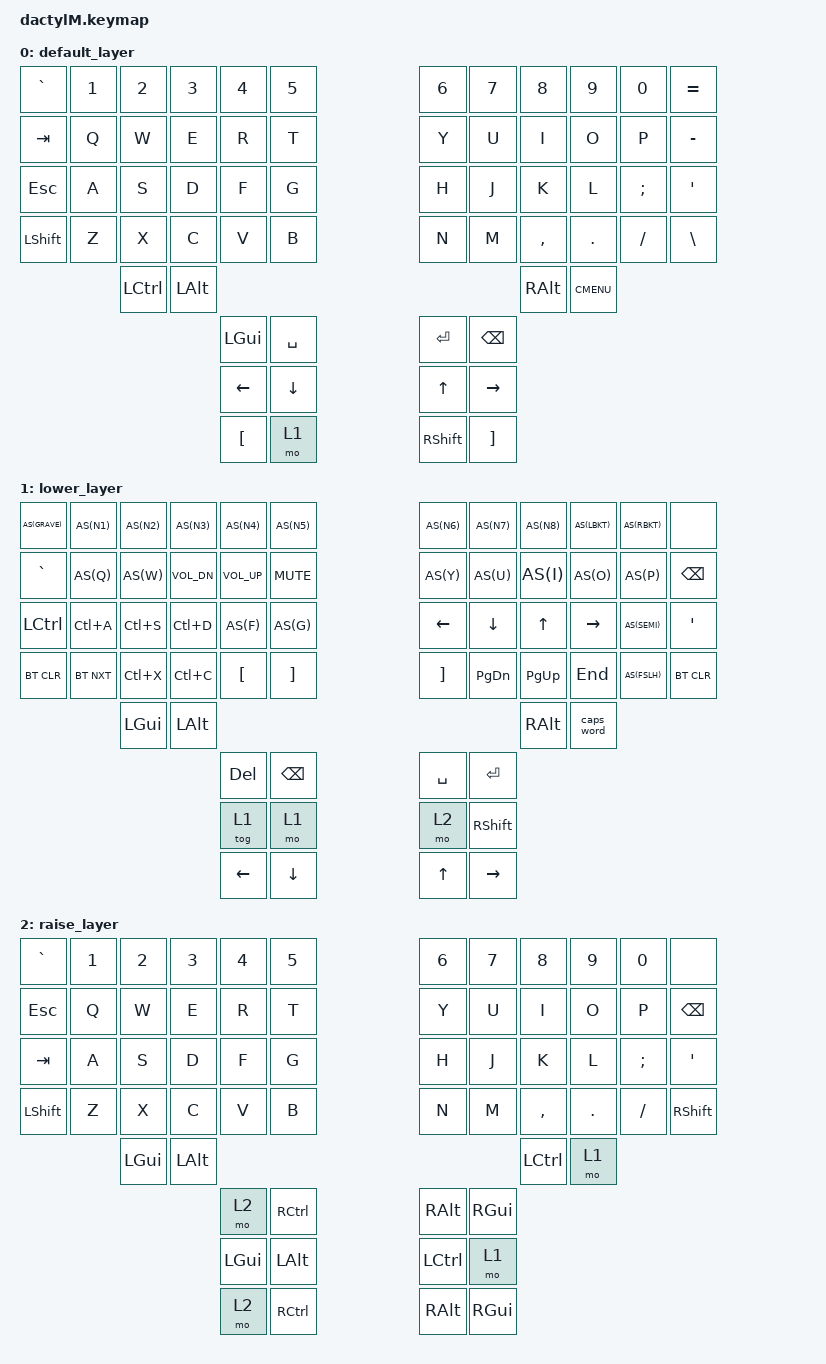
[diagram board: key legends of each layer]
/*
 * Copyright (c) 2020 The ZMK Contributors
 *
 * SPDX-License-Identifier: MIT
 */
/**/

#include <behaviors.dtsi>
#include <dt-bindings/zmk/keys.h>
#include <dt-bindings/zmk/bt.h>



#define DEFAULT 0
#define Movement 1
#define NumPad 2
#define Macro 3
#define Mouse 4

#define AS(keycode) &as LS(keycode) keycode

/ {
        behaviors {
            as: auto_shift {
                compatible = "zmk,behavior-hold-tap";
                label = "AUTO_SHIFT";
                #binding-cells = <2>;
                tapping_term_ms = <200>;
                quick_tap_ms = <10>;
                flavor = "tap-preferred";
                bindings = <&kp>, <&kp>;
            };
        };


    keymap {
        compatible = "zmk,keymap";

        default_layer {
// ------------------------------------------------------------------------------------------------------------
// |  ESC  |  1  |  2  |  3   |  4   |  5    |                   |  6   |  7     |  8    |  9   |   0   | CLR_BT |
// |  TAB  |  Q  |  W  |  E   |  R   |  T    |                   |  Y   |  U     |  I    |  O   |   P   | BKSPC  |
// |  CTRL |  A  |  S  |  D   |  F   |  G    |                   |  H   |  J     |  K    |  L   |   ;   |   '    |
// | SHIFT |  Z  |  X  |  C   |  V   |  B    |                   |  N   |  M     |  ,    |  .   |   /   | SHIFT  |
//               | GUI | ALT  |                                                  | ALT   | GUI  |
//                            | DEL  | BKSPC |                   | SPACE | ENTR  |
//                            | Lyr4 | Lyr1  |                   | Lyr2  | Lyr3  |
//                            | LEFT | DOWN  |                   | UP    | RIGHT |
            bindings = <
&kp GRAVE  &kp N1  &kp N2   &kp N3  &kp N4    &kp N5                      &kp N6 &kp N7    &kp N8    &kp N9   &kp N0   &kp EQUAL
&kp TAB    &kp Q  &kp W    &kp E    &kp R     &kp T                       &kp Y  &kp U     &kp I     &kp O    &kp P    &kp MINUS
&kp ESC    &kp A  &kp S    &kp D    &kp F     &kp G                       &kp H  &kp J     &kp K     &kp L    &kp SEMI &kp SQT
&kp LSHFT  &kp Z  &kp X    &kp C    &kp V     &kp B                       &kp N  &kp M     &kp COMMA &kp DOT  &kp FSLH &kp BSLH
                 &kp LCTL &kp LALT                                                        &kp RALT  &kp K_CMENU
                                    &kp LGUI  &kp SPACE                  &kp ENTER  &kp BSPC
                                    &kp LEFT &kp DOWN                    &kp UP     &kp RIGHT
                                    &kp LEFT_BRACKET      &mo 1          &kp RSHFT  &kp RIGHT_BRACKET
            >;
        };

        lower_layer {
// TODO: Some binds are waiting for shifted keycode support.
// ------------------------------------------------------------------------------------------------------------
// |       |  F1 |  F2 |  F3  |  F4  |  F5  |                   |  F6  |  F7   |  F8   |  F9  |  F10  |  F11  |
// | `     |   1 |   2 |   3  |   4  |   5  |                   |   6  |   7   |   8   |   9  |    0  |  F12  |
// |       |  !  |  @  |  #   |  $   |  %   |                   |  ^   |  &    |  *    |  (   |   )   |   |   |
// |       |  =  |  -  |  +   |  {   |  }   |        |  |       |  [   |  ]    |  ;    |  :   |   \   |       |
//               |     |      |      |      |        |  |       |      |       |       |      |
           bindings = <
AS(GRAVE)   AS(N1)      AS(N2)    AS(N3)    AS(N4) AS(N5)                  AS(N6)   AS(N7)    AS(N8)    AS(LBKT)     AS(RBKT)   &none
&kp GRAVE   AS(Q)       AS(W)     &kp K_VOL_DN &kp K_VOL_UP  &kp K_MUTE    AS(Y)    AS(U)     AS(I)     AS(O)      AS(P)    &kp BSPC
&kp LCTRL   &kp LC(A)   &kp LC(S) &kp LC(D) AS(F)  AS(G)                   &kp LEFT &kp DOWN  &kp UP    &kp RIGHT AS(SEMI) &kp SQT
&bt BT_CLR  &bt BT_NXT  &kp LC(X) &kp LC(C) &kp LEFT_BRACKET  &kp RIGHT_BRACKET        &kp RIGHT_BRACKET &kp PG_DN &kp PG_UP &kp END    AS(FSLH) &bt BT_CLR
                       &kp LGUI  &kp LALT                                                    &kp RALT  &caps_word
                                   &kp DELETE  &kp BSPC                   &kp SPACE &kp ENTER
                                   &tog 1       &mo 1                     &mo 2     &kp RSHFT
                                   &kp LEFT    &kp DOWN                   &kp UP    &kp RIGHT
            >;
       
        };

        raise_layer {
// ------------------------------------------------------------------------------------------------------------
// |BTCLR| BT1  | BT2  |  BT3  |  BT4  |  BT5 |                |      |      |       |      |       |       |
// |     | INS  | PSCR | GUI   |       |      |                | PGUP |      |   ^   |      |       |       |
// |     | ALT  | CTRL | SHIFT |       | CAPS |                | PGDN |   <- |   v   |  ->  |  DEL  | BKSPC |
// |     | UNDO | CUT  | COPY  | PASTE |      |      |  |      |      |      |       |      |       |       |
//              |      |       |       |      |      |  |      |      |      |       |      |
           bindings = <
&kp GRAVE &kp N1 &kp N2   &kp N3   &kp N4    &kp N5                      &kp N6 &kp N7    &kp N8    &kp N9   &kp N0   &none
&kp ESC   &kp Q  &kp W    &kp E    &kp R     &kp T                       &kp Y  &kp U     &kp I     &kp O    &kp P    &kp BSPC
&kp TAB   &kp A  &kp S    &kp D    &kp F     &kp G                       &kp H  &kp J     &kp K     &kp L    &kp SEMI &kp SQT
&kp LSHFT &kp Z  &kp X    &kp C    &kp V     &kp B                       &kp N  &kp M     &kp COMMA &kp DOT  &kp FSLH &kp RSHFT
                 &kp LGUI &kp LALT &kp LCTRL &mo 1                       &mo 2  &kp RCTRL &kp RALT  &kp RGUI
                 &kp LGUI &kp LALT &kp LCTRL &mo 1                       &mo 2  &kp RCTRL &kp RALT  &kp RGUI                 
            >;
  
        };
    };
};
